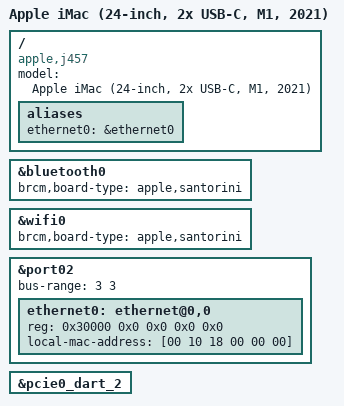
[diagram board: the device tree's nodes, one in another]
/dts-v1/;
#include "t8103.dtsi"
#include "t8103-jxxx.dtsi"
/ {
	compatible = "apple,j457", "apple,t8103", "apple,arm-platform";
	model = "Apple iMac (24-inch, 2x USB-C, M1, 2021)";
	aliases {
		ethernet0 = &ethernet0;
	};
};
&bluetooth0 {
	brcm,board-type = "apple,santorini";
};
&wifi0 {
	brcm,board-type = "apple,santorini";
};
&port02 {
	bus-range = <3 3>;
	status = "okay";
	ethernet0: ethernet@0,0 {
		reg = <0x30000 0x0 0x0 0x0 0x0>;
		local-mac-address = [00 10 18 00 00 00];
	};
};
&pcie0_dart_2 {
	status = "okay";
};
